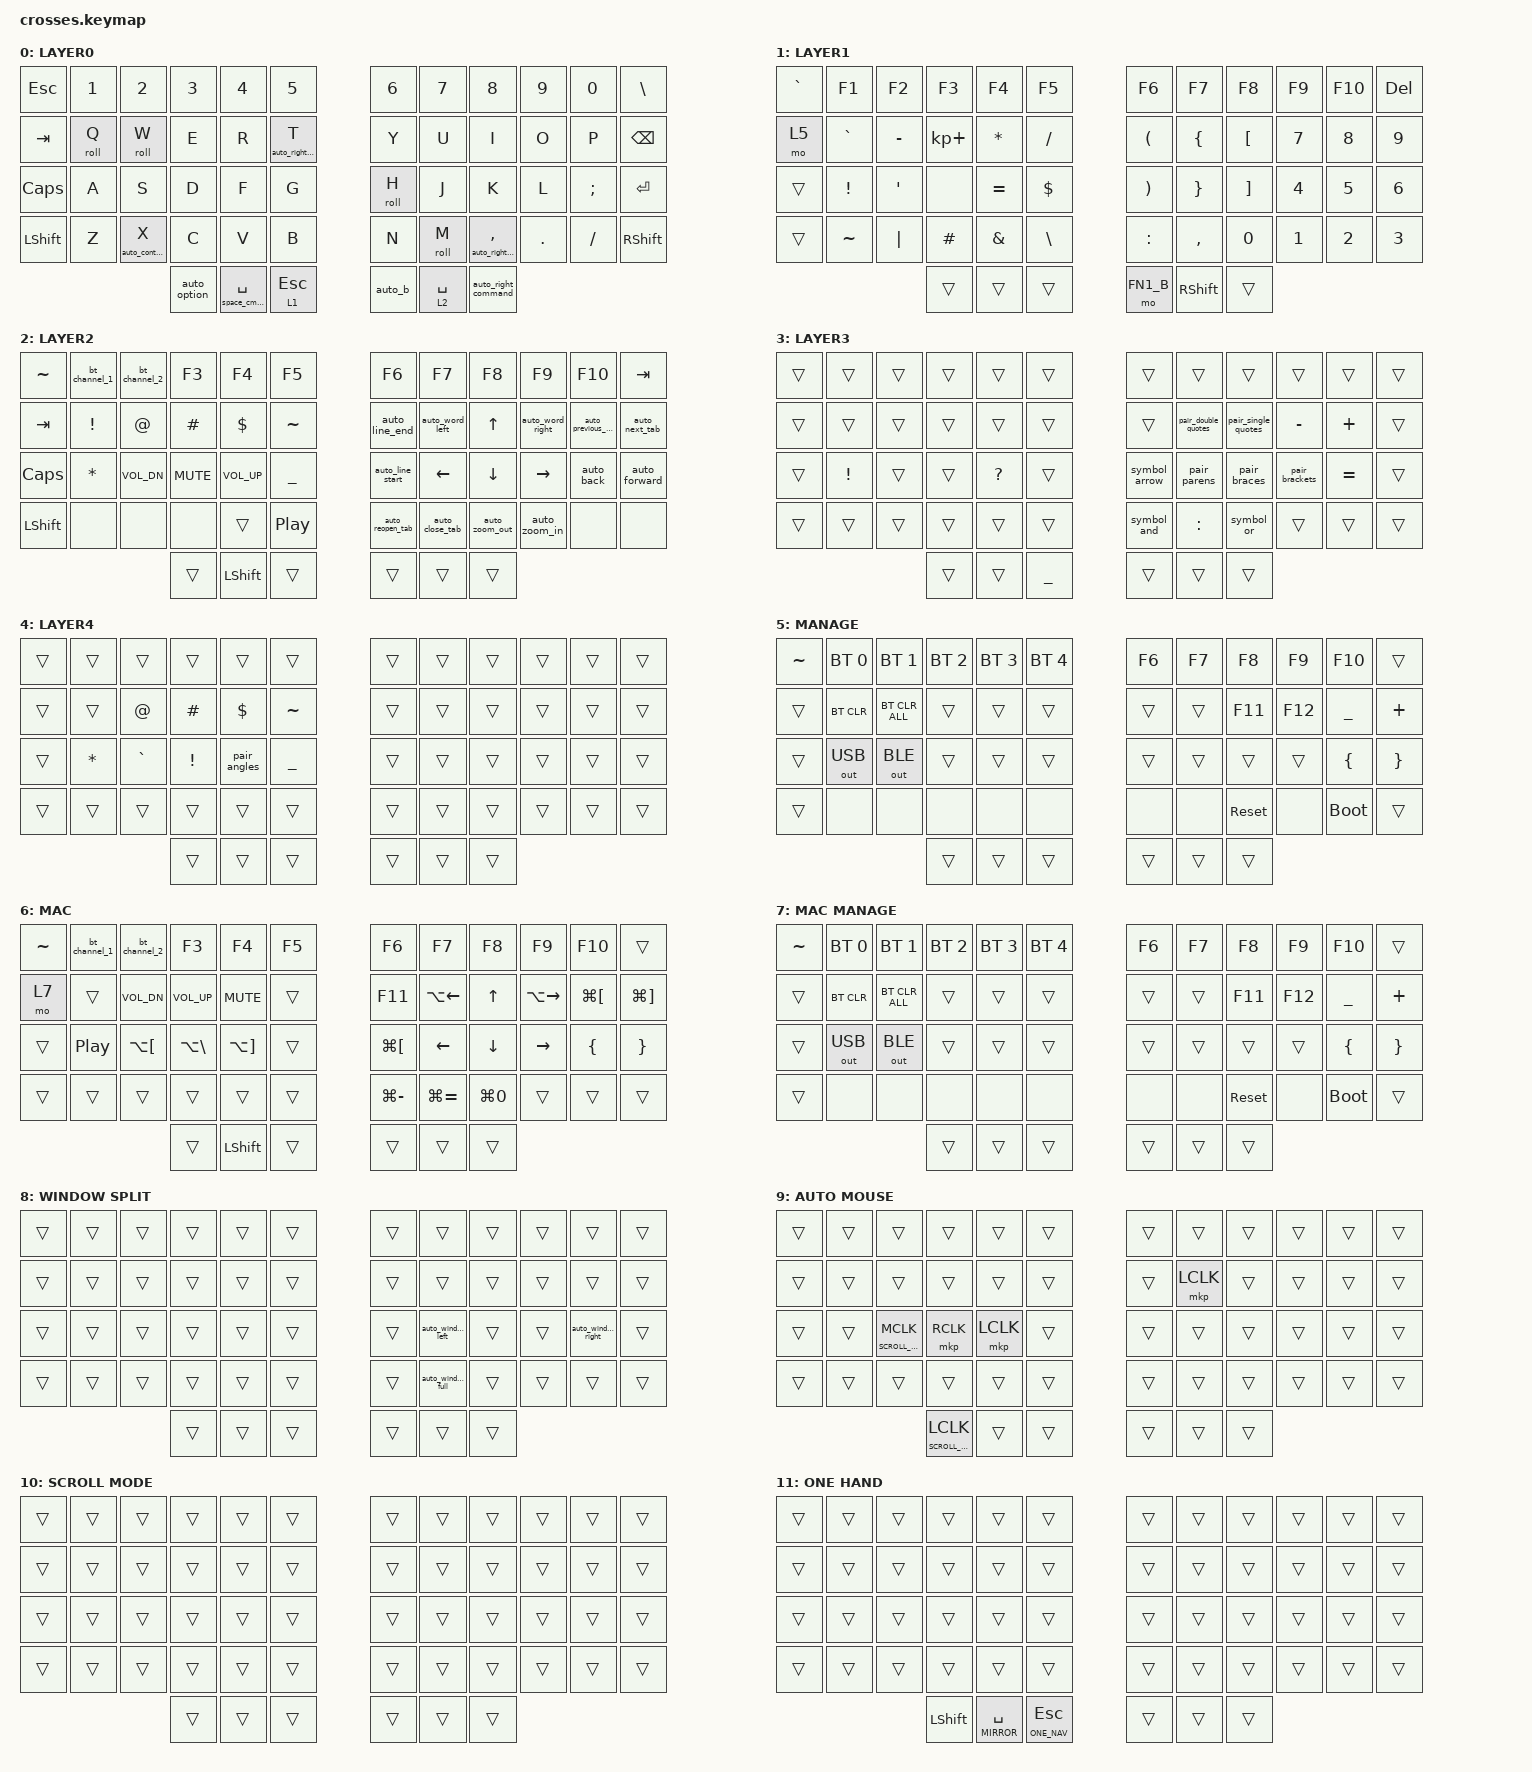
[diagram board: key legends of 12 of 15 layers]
/*
 * Crosses 54 keymap ported from semi1204/sofle-keyboard-config (codex/ctrl-rightclick-thumb, f4feaf1).
 * Sofle middle column, encoders, RGB and soft-off do not exist on Crosses.
 * Thumbs: L Option / Space-Cmd / Fn1-Esc, R B-Ctrl / Space-Fn2 / RCmd.
 */

#include <behaviors.dtsi>
#include <input/processors.dtsi>
#include <dt-bindings/zmk/bt.h>
#include <dt-bindings/zmk/keys.h>
#include <dt-bindings/zmk/outputs.h>
#include <dt-bindings/zmk/pointing.h>
#include <dt-bindings/zmk/input_transform.h>
#include <zephyr/dt-bindings/input/input-event-codes.h>

#define AUTO_MOUSE 9
#define SCROLL_MODE 10
#define ONE_HAND 11
#define MIRROR 12
#define ONE_NAV 13
#define FN1_B 14

&lt {
    flavor = "hold-preferred";
    tapping-term-ms = <150>;
};

// Moving the right (pointer) trackball turns on AUTO_MOUSE for 1000 ms after the last movement.
// Any key other than excluded-positions turns it off immediately.
&zip_temp_layer {
    require-prior-idle-ms = <300>;
    excluded-positions = <19 26 27 28 36 38 48 49>;
};

// Right ball = pointer: x1.75 (stock cpi 700 felt slow).
&trackball_central_listener {
    input-processors = <&zip_xy_scaler 7 4>, <&zip_temp_layer AUTO_MOUSE 1000>, <&zip_ble_report_rate_limit>;

    // Holding S or the left Option thumb on AUTO_MOUSE turns the right ball into a scroll wheel.
    scroll_mode {
        layers = <SCROLL_MODE>;
        input-processors = <&zip_xy_to_scroll_mapper>, <&zip_scroll_transform INPUT_TRANSFORM_Y_INVERT>, <&zip_scroll_scaler 1 32>, <&zip_temp_layer AUTO_MOUSE 1000>, <&zip_ble_report_rate_limit>;
    };

    // Fn1 + B held: one flick up on the right ball runs Screen OCR. Listed before fn1_keys because
    // the first override whose layer is active wins.
    fn1_b_keys {
        layers = <FN1_B>;
        input-processors = <&zip_xy_to_scroll_mapper>, <&zip_scroll_transform INPUT_TRANSFORM_Y_INVERT>, <&zip_scroll_scaler 1 4>, <&zip_scroll_ocr>;
    };

    // Fn1 held: the right ball is a two-way switch, one tap per flick (up = Ctrl+1, down = Option+/).
    fn1_keys {
        layers = <1>;
        input-processors = <&zip_xy_to_scroll_mapper>, <&zip_scroll_transform INPUT_TRANSFORM_Y_INVERT>, <&zip_scroll_scaler 1 4>, <&zip_scroll_fn1>;
    };
};

// Left ball = scroll at 1/32 (stock 1/4 felt too fast).
&trackball_peripheral_listener {
    input-processors = <&zip_xy_to_scroll_mapper>, <&zip_scroll_scaler 1 32>, <&zip_ble_report_rate_limit>;

    // On Fn2 the left ball zooms (Cmd +/-) instead of scrolling.
    zoom {
        layers = <2>;
        input-processors = <&zip_xy_to_scroll_mapper>, <&zip_scroll_scaler 1 4>, <&zip_scroll_zoom>;
    };
};

/ {
    chosen { zmk,physical-layout = &gggw_crosses_54_layout; };

    zip_scroll_zoom: zip_scroll_zoom {
        compatible = "zmk,input-processor-scroll-keys";
        #input-processor-cells = <0>;
        code = <INPUT_REL_WHEEL>;
        threshold = <40>;
        bindings = <&auto_zoom_in>, <&auto_zoom_out>;
    };

    // Fn1 right ball: Ctrl+1 (up) / Option+/ (down) for Screenshot X and BTT, once per flick.
    zip_scroll_fn1: zip_scroll_fn1 {
        compatible = "zmk,input-processor-scroll-keys";
        #input-processor-cells = <0>;
        code = <INPUT_REL_WHEEL>;
        threshold = <60>;
        one-shot-idle-ms = <300>;
        bindings = <&kp LC(N1)>, <&auto_option_slash>;
    };

    // Fn1 + B right ball: flick up = Option+Shift+2 (Raycast ScreenOCR hotkey).
    zip_scroll_ocr: zip_scroll_ocr {
        compatible = "zmk,input-processor-scroll-keys";
        #input-processor-cells = <0>;
        code = <INPUT_REL_WHEEL>;
        threshold = <60>;
        one-shot-idle-ms = <300>;
        bindings = <&auto_screen_ocr>, <&none>;
    };

    behaviors {
        // The Windows profile (BLE profile 1, the second slot, used by both the Windows and the Linux host)
        // sends what the laptop's own keys send at the Mac positions: Option = LGUI, Command = LALT,
        // Control = LCTRL, right Command = RALT. Each host remaps from there (Windows: SharpKeys LWin->Alt,
        // LAlt->Ctrl, LCtrl->Win plus AHK Alt+arrow word moves; Linux: kanata -> Toshy), so Option, Command
        // and Control stay distinct. Mac shortcuts with modifiers must go through a profile modifier, never a
        // raw LA()/LG().
        auto_option: auto_option {
            compatible = "zmk,behavior-profile-modifier";
            #binding-cells = <0>;
            windows-profile = <1>;
            bindings = <&kp LEFT_ALT>, <&kp LEFT_GUI>;
            display-name = "Auto Option / Win";
        };

        auto_command: auto_command {
            compatible = "zmk,behavior-profile-modifier";
            #binding-cells = <0>;
            windows-profile = <1>;
            bindings = <&kp LEFT_GUI>, <&kp LEFT_ALT>;
            display-name = "Auto Command / Alt";
        };

        // Windows host remaps raw RAlt/SC138 to Ctrl and LGUI to ordinary LAlt.
        auto_space: auto_space {
            compatible = "zmk,behavior-profile-modifier";
            #binding-cells = <0>;
            windows-profile = <1>;
            bindings = <&mt RIGHT_GUI SPACE>, <&mt RIGHT_ALT SPACE>;
            display-name = "Auto Space / Cmd-Ctrl";
        };

        space_shift: space_shift {
            compatible = "zmk,behavior-hold-tap";
            #binding-cells = <2>;
            flavor = "tap-preferred";
            tapping-term-ms = <200>;
            bindings = <&kp>, <&kp>;
            display-name = "Space / Shift";
        };

        // retro-tap: held past 150 ms and released alone still gives Space (RCmd+Space).
        space_fn2: space_fn2 {
            compatible = "zmk,behavior-hold-tap";
            #binding-cells = <2>;
            flavor = "tap-preferred";
            tapping-term-ms = <150>;
            retro-tap;
            bindings = <&mo>, <&kp>;
            display-name = "Space / Fn2";
        };

        auto_right_command: auto_right_command {
            compatible = "zmk,behavior-profile-modifier";
            #binding-cells = <0>;
            windows-profile = <1>;
            bindings = <&kp RIGHT_GUI>, <&kp RIGHT_ALT>;
            display-name = "Auto Right Command / Ctrl";
        };

        auto_right_alt: auto_right_alt {
            compatible = "zmk,behavior-profile-modifier";
            #binding-cells = <0>;
            windows-profile = <1>;
            bindings = <&kp RIGHT_ALT>, <&kp LEFT_GUI>;
            display-name = "Auto Right Alt / Alt";
        };

        // Control is LCTRL on both profiles.
        auto_control: auto_control {
            compatible = "zmk,behavior-profile-modifier";
            #binding-cells = <0>;
            windows-profile = <1>;
            bindings = <&kp LCTRL>, <&kp LCTRL>;
            display-name = "Auto Control";
        };

        // B follows typing like Space: within 250 ms of a key it is always B; after a pause, any key
        // pressed while it is held is Ctrl+key at once; a long press released alone still gives B.
        b_ctrl: b_ctrl {
            compatible = "zmk,behavior-hold-tap";
            #binding-cells = <2>;
            flavor = "hold-preferred";
            tapping-term-ms = <200>;
            quick-tap-ms = <175>;
            require-prior-idle-ms = <250>;
            retro-tap;
            bindings = <&kp>, <&kp>;
            display-name = "Hold Control / Tap B";
        };

        // B/Control is LCTRL on both profiles.
        auto_b: auto_b {
            compatible = "zmk,behavior-profile-modifier";
            #binding-cells = <0>;
            windows-profile = <1>;
            bindings = <&b_ctrl LCTRL B>, <&b_ctrl LCTRL B>;
            display-name = "Auto B / Ctrl";
        };

        auto_back: auto_back {
            compatible = "zmk,behavior-profile-modifier";
            #binding-cells = <0>;
            windows-profile = <1>;
            bindings = <&kp LG(LEFT_BRACKET)>, <&kp C_AC_BACK>;
            display-name = "Auto Back";
        };

        auto_forward: auto_forward {
            compatible = "zmk,behavior-profile-modifier";
            #binding-cells = <0>;
            windows-profile = <1>;
            bindings = <&kp LG(RIGHT_BRACKET)>, <&kp C_AC_FORWARD>;
            display-name = "Auto Forward";
        };

        // This Windows host maps raw Left Alt to Ctrl.
        auto_previous_tab: auto_previous_tab {
            compatible = "zmk,behavior-profile-modifier";
            #binding-cells = <0>;
            windows-profile = <1>;
            bindings = <&kp LG(LS(LEFT_BRACKET))>, <&kp LA(PG_UP)>;
            display-name = "Auto Previous Tab";
        };

        auto_next_tab: auto_next_tab {
            compatible = "zmk,behavior-profile-modifier";
            #binding-cells = <0>;
            windows-profile = <1>;
            bindings = <&kp LG(LS(RIGHT_BRACKET))>, <&kp LA(PG_DN)>;
            display-name = "Auto Next Tab";
        };

        auto_reopen_tab: auto_reopen_tab {
            compatible = "zmk,behavior-profile-modifier";
            #binding-cells = <0>;
            windows-profile = <1>;
            bindings = <&kp LG(LS(T))>, <&kp LA(LS(T))>;
            display-name = "Auto Reopen Tab";
        };

        auto_close_tab: auto_close_tab {
            compatible = "zmk,behavior-profile-modifier";
            #binding-cells = <0>;
            windows-profile = <1>;
            bindings = <&kp LG(W)>, <&kp LA(W)>;
            display-name = "Auto Close Tab";
        };

        auto_zoom_in: auto_zoom_in {
            compatible = "zmk,behavior-profile-modifier";
            #binding-cells = <0>;
            windows-profile = <1>;
            bindings = <&kp LG(EQUAL)>, <&kp LA(EQUAL)>;
            display-name = "Auto Zoom In";
        };

        auto_zoom_out: auto_zoom_out {
            compatible = "zmk,behavior-profile-modifier";
            #binding-cells = <0>;
            windows-profile = <1>;
            bindings = <&kp LG(MINUS)>, <&kp LA(MINUS)>;
            display-name = "Auto Zoom Out";
        };

        auto_undo: auto_undo {
            compatible = "zmk,behavior-profile-modifier";
            #binding-cells = <0>;
            windows-profile = <1>;
            bindings = <&kp LG(Z)>, <&kp LA(Z)>;
            display-name = "Auto Undo";
        };

        auto_cut: auto_cut {
            compatible = "zmk,behavior-profile-modifier";
            #binding-cells = <0>;
            windows-profile = <1>;
            bindings = <&kp LG(X)>, <&kp LA(X)>;
            display-name = "Auto Cut";
        };

        auto_copy: auto_copy {
            compatible = "zmk,behavior-profile-modifier";
            #binding-cells = <0>;
            windows-profile = <1>;
            bindings = <&kp LG(C)>, <&kp LA(C)>;
            display-name = "Auto Copy";
        };

        auto_paste: auto_paste {
            compatible = "zmk,behavior-profile-modifier";
            #binding-cells = <0>;
            windows-profile = <1>;
            bindings = <&kp LG(V)>, <&kp LA(V)>;
            display-name = "Auto Paste";
        };

        // One-shot modifiers for ONE_NAV, same host mapping as auto_command/auto_option/auto_control.
        sticky_command: sticky_command {
            compatible = "zmk,behavior-profile-modifier";
            #binding-cells = <0>;
            windows-profile = <1>;
            bindings = <&sk LEFT_GUI>, <&sk LEFT_ALT>;
            display-name = "Sticky Command";
        };

        sticky_option: sticky_option {
            compatible = "zmk,behavior-profile-modifier";
            #binding-cells = <0>;
            windows-profile = <1>;
            bindings = <&sk LEFT_ALT>, <&sk LEFT_GUI>;
            display-name = "Sticky Option";
        };

        // Control is LCTRL on both profiles.
        sticky_control: sticky_control {
            compatible = "zmk,behavior-profile-modifier";
            #binding-cells = <0>;
            windows-profile = <1>;
            bindings = <&sk LCTRL>, <&sk LCTRL>;
            display-name = "Sticky Control";
        };

        auto_line_start: auto_line_start {
            compatible = "zmk,behavior-profile-modifier";
            #binding-cells = <0>;
            windows-profile = <1>;
            bindings = <&kp LG(LEFT)>, <&kp HOME>;
            display-name = "Auto Line Start";
        };

        auto_line_end: auto_line_end {
            compatible = "zmk,behavior-profile-modifier";
            #binding-cells = <0>;
            windows-profile = <1>;
            bindings = <&kp LG(RIGHT)>, <&kp END>;
            display-name = "Auto Line End";
        };

        // Option+arrow word moves (Windows: SharpKeys turns LGUI into Alt, then AHK turns Alt+arrow into Ctrl+arrow;
        // Toshy does the same on Linux).
        auto_word_left: auto_word_left {
            compatible = "zmk,behavior-profile-modifier";
            #binding-cells = <0>;
            windows-profile = <1>;
            bindings = <&kp LA(LEFT)>, <&kp LG(LEFT)>;
            display-name = "Auto Word Left";
        };

        auto_word_right: auto_word_right {
            compatible = "zmk,behavior-profile-modifier";
            #binding-cells = <0>;
            windows-profile = <1>;
            bindings = <&kp LA(RIGHT)>, <&kp LG(RIGHT)>;
            display-name = "Auto Word Right";
        };

        auto_select_word_right: auto_select_word_right {
            compatible = "zmk,behavior-profile-modifier";
            #binding-cells = <0>;
            windows-profile = <1>;
            bindings = <&kp LA(LS(RIGHT))>, <&kp LG(LS(RIGHT))>;
            display-name = "Auto Select Word Right";
        };

        auto_paste_style: auto_paste_style {
            compatible = "zmk,behavior-profile-modifier";
            #binding-cells = <0>;
            windows-profile = <1>;
            bindings = <&kp LG(LS(V))>, <&kp LA(LS(V))>;
            display-name = "Auto Paste and Match Style";
        };

        auto_window_left: auto_window_left {
            compatible = "zmk,behavior-profile-modifier";
            #binding-cells = <0>;
            windows-profile = <1>;
            bindings = <&kp LA(LEFT_BRACKET)>, <&kp LC(LEFT)>;
            display-name = "Auto Window Left";
        };

        auto_window_right: auto_window_right {
            compatible = "zmk,behavior-profile-modifier";
            #binding-cells = <0>;
            windows-profile = <1>;
            bindings = <&kp LA(RIGHT_BRACKET)>, <&kp LC(RIGHT)>;
            display-name = "Auto Window Right";
        };

        auto_window_full: auto_window_full {
            compatible = "zmk,behavior-profile-modifier";
            #binding-cells = <0>;
            windows-profile = <1>;
            bindings = <&kp LA(BSLH)>, <&kp LC(UP)>;
            display-name = "Auto Window Full";
        };

        auto_option_slash: auto_option_slash {
            compatible = "zmk,behavior-profile-modifier";
            #binding-cells = <0>;
            windows-profile = <1>;
            bindings = <&kp LA(FSLH)>, <&kp LG(FSLH)>;
            display-name = "Auto Option Slash";
        };

        // Raycast ScreenOCR hotkey: Option+Shift+2.
        auto_screen_ocr: auto_screen_ocr {
            compatible = "zmk,behavior-profile-modifier";
            #binding-cells = <0>;
            windows-profile = <1>;
            bindings = <&kp LA(LS(N2))>, <&kp LG(LS(N2))>;
            display-name = "Auto Screen OCR";
        };

        layer_click: layer_click {
            compatible = "zmk,behavior-hold-tap";
            #binding-cells = <2>;
            flavor = "tap-preferred";
            tapping-term-ms = <200>;
            bindings = <&mo>, <&mkp>;
            display-name = "Layer Click";
        };

        hold_ctrl: hold_ctrl {
            compatible = "zmk,behavior-hold-tap";
            #binding-cells = <2>;
            flavor = "tap-preferred";
            tapping-term-ms = <350>;
            bindings = <&auto_control>, <&kp>;
            display-name = "Hold Control / Tap Key";
        };

        hold_right_alt: hold_right_alt {
            compatible = "zmk,behavior-hold-tap";
            #binding-cells = <2>;
            flavor = "tap-preferred";
            tapping-term-ms = <350>;
            bindings = <&auto_right_alt>, <&kp>;
            display-name = "Hold Right Option / Tap Key";
        };

        // AUTO_MOUSE left thumb: tap = left click (quick re-taps for double/triple click),
        // hold past 150 ms = right-ball scroll (no Option).
        scroll_click: scroll_click {
            compatible = "zmk,behavior-hold-tap";
            #binding-cells = <2>;
            flavor = "balanced";
            tapping-term-ms = <150>;
            quick-tap-ms = <300>;
            bindings = <&mo>, <&mkp>;
            display-name = "Hold Scroll / Tap Click";
        };

        // ONE_HAND Space: any key pressed while it is down is mirrored; alone it is Space.
        space_mirror: space_mirror {
            compatible = "zmk,behavior-hold-tap";
            #binding-cells = <2>;
            flavor = "hold-preferred";
            tapping-term-ms = <200>;
            retro-tap;
            bindings = <&mo>, <&kp>;
            display-name = "Space / Mirror";
        };

        // Space follows typing: within 250 ms of a letter it is always Space. After a pause,
        // any key pressed while it is held is Cmd+key at once (release order no longer matters),
        // and a long press released alone still gives Space (so RCmd+Space works).
        // Q, W, H and M are &roll keys (modules/roll-guard): rolled into from this thumb they wait.
        // Letter released first = Cmd+letter; thumb released first = it was typing, so Space and
        // the letter are typed. That keeps typing from quitting, closing, hiding or minimizing a
        // window while a quick Cmd+W still works. After 200 ms of holding they are plain Cmd keys.
        space_cmd_hold: space_cmd_hold {
            compatible = "zmk,behavior-roll-guard-hold";
            #binding-cells = <0>;
            bindings = <&auto_command>, <&kp SPACE>;
            quick-ms = <200>;
            display-name = "Space/Command hold";
        };

        roll: roll {
            compatible = "zmk,behavior-roll-guard";
            #binding-cells = <1>;
            display-name = "Roll-safe Key";
        };

        space_cmd: space_cmd {
            compatible = "zmk,behavior-hold-tap";
            #binding-cells = <2>;
            flavor = "hold-preferred";
            tapping-term-ms = <200>;
            quick-tap-ms = <175>;
            require-prior-idle-ms = <250>;
            retro-tap;
            bindings = <&space_cmd_hold>, <&kp>;
            display-name = "Hold Command / Tap Space";
        };
    };

    combos {
        compatible = "zmk,combos";

        // Combos execute on the central (left half); MANAGE's right-hand keys reach the right half.
        combo_left_bootloader {
            timeout-ms = <50>;
            key-positions = <37 38>;
            bindings = <&bootloader>;
            layers = <5 7>;
        };
        combo_left_reset {
            timeout-ms = <50>;
            key-positions = <39 40>;
            bindings = <&sys_reset>;
            layers = <5 7>;
        };
        // Keep Fn1 Tab management access reachable even with a saved runtime keymap.
        combo_fn1_manage {
            timeout-ms = <50>;
            key-positions = <12>;
            bindings = <&mo 5>;
            layers = <1>;
        };
        // Space + Fn1/Esc thumbs toggle one-handed mode.
        combo_one_hand {
            timeout-ms = <50>;
            key-positions = <49 50>;
            bindings = <&tog ONE_HAND>;
            layers = <0 ONE_HAND>;
        };
        combo_sd_symbols {
            timeout-ms = <50>;
            key-positions = <26 27>;
            bindings = <&mo 3>;
            layers = <0>;
        };
        combo_jn_symbols {
            timeout-ms = <50>;
            key-positions = <31 42>;
            bindings = <&mo 4>;
            layers = <0>;
        };
        combo_kl_option {
            timeout-ms = <50>;
            key-positions = <32 33>;
            bindings = <&mo 8>;
            layers = <0>;
        };
        combo_df_command {
            timeout-ms = <50>;
            key-positions = <27 28>;
            bindings = <&auto_right_command>;
            layers = <0 ONE_HAND>;
        };
        combo_jk_delete_word {
            timeout-ms = <50>;
            key-positions = <31 32>;
            bindings = <&delete_word>;
            layers = <0>;
        };
        // JK mirrored for one-handed mode: hold Space, then D+F.
        combo_mirror_delete_word {
            timeout-ms = <50>;
            key-positions = <27 28>;
            bindings = <&delete_word>;
            layers = <MIRROR>;
        };
        combo_jl_delete_line {
            timeout-ms = <50>;
            key-positions = <31 33>;
            bindings = <&delete_line>;
            layers = <0>;
        };
        combo_zx_caps_lock {
            timeout-ms = <50>;
            key-positions = <37 38>;
            bindings = <&kp CAPS>;
            layers = <0>;
        };
        combo_xc_escape {
            timeout-ms = <30>;
            key-positions = <38 39>;
            bindings = <&kp ESC>;
            layers = <0>;
        };
        combo_paste_style {
            timeout-ms = <50>;
            key-positions = <34 35>;
            bindings = <&auto_paste_style>;
            layers = <0>;
        };
        combo_qw_escape {
            timeout-ms = <30>;
            key-positions = <13 14>;
            bindings = <&kp ESC>;
            layers = <0>;
        };
        combo_comma_dot_enter {
            timeout-ms = <50>;
            key-positions = <44 45>;
            bindings = <&kp ENTER>;
            layers = <0>;
        };
    };

    macros {
        bt_channel_1: bt_channel_1 {
            compatible = "zmk,behavior-macro";
            #binding-cells = <0>;
            tap-ms = <0>;
            wait-ms = <0>;
            bindings = <&bt BT_SEL 0 &out OUT_BLE>;
            display-name = "Bluetooth 1 (Mac)";
        };
        bt_channel_2: bt_channel_2 {
            compatible = "zmk,behavior-macro";
            #binding-cells = <0>;
            tap-ms = <0>;
            wait-ms = <0>;
            bindings = <&bt BT_SEL 1 &out OUT_BLE>;
            display-name = "Bluetooth 2 (Windows)";
        };

        pair_parens: pair_parens {
            compatible = "zmk,behavior-macro";
            #binding-cells = <0>;
            tap-ms = <40>;
            wait-ms = <40>;
            bindings = <&kp LPAR &kp RPAR &kp LEFT>;
        };
        pair_braces: pair_braces {
            compatible = "zmk,behavior-macro";
            #binding-cells = <0>;
            tap-ms = <40>;
            wait-ms = <40>;
            bindings = <&kp LBRC &kp RBRC &kp LEFT>;
        };
        pair_brackets: pair_brackets {
            compatible = "zmk,behavior-macro";
            #binding-cells = <0>;
            tap-ms = <40>;
            wait-ms = <40>;
            bindings = <&kp LBKT &kp RBKT &kp LEFT>;
        };
        pair_double_quotes: pair_double_quotes {
            compatible = "zmk,behavior-macro";
            #binding-cells = <0>;
            tap-ms = <40>;
            wait-ms = <40>;
            bindings = <&kp DQT &kp DQT &kp LEFT>;
        };
        pair_single_quotes: pair_single_quotes {
            compatible = "zmk,behavior-macro";
            #binding-cells = <0>;
            tap-ms = <40>;
            wait-ms = <40>;
            bindings = <&kp APOS &kp APOS &kp LEFT>;
        };
        pair_angles: pair_angles {
            compatible = "zmk,behavior-macro";
            #binding-cells = <0>;
            tap-ms = <40>;
            wait-ms = <40>;
            bindings = <&kp LT &kp GT &kp LEFT>;
        };
        delete_word: delete_word {
            compatible = "zmk,behavior-macro";
            #binding-cells = <0>;
            tap-ms = <40>;
            wait-ms = <40>;
            bindings = <&auto_word_left &auto_select_word_right &kp BACKSPACE>;
        };
        delete_line: delete_line {
            compatible = "zmk,behavior-macro";
            #binding-cells = <0>;
            tap-ms = <40>;
            wait-ms = <40>;
            bindings = <&auto_line_start &auto_line_start &kp LS(DOWN) &kp BACKSPACE>;
        };
        symbol_arrow: symbol_arrow {
            compatible = "zmk,behavior-macro";
            #binding-cells = <0>;
            tap-ms = <40>;
            wait-ms = <40>;
            bindings = <&kp EQUAL &kp GT>;
        };
        symbol_and: symbol_and {
            compatible = "zmk,behavior-macro";
            #binding-cells = <0>;
            tap-ms = <40>;
            wait-ms = <40>;
            bindings = <&kp AMPERSAND &kp AMPERSAND>;
        };
        symbol_or: symbol_or {
            compatible = "zmk,behavior-macro";
            #binding-cells = <0>;
            tap-ms = <40>;
            wait-ms = <40>;
            bindings = <&kp PIPE &kp PIPE>;
        };

        SHIFT_MCLK: SHIFT_MCLK {
            compatible = "zmk,behavior-macro";
            #binding-cells = <0>;
            bindings =
                <&macro_press>,
                <&kp LEFT_SHIFT>,
                <&macro_press>,
                <&mkp MB3>,
                <&macro_pause_for_release>,
                <&macro_release>,
                <&kp LEFT_SHIFT &mkp MB3>;

            label = "SHIFT_MCLK";
        };
    };

    keymap {
        compatible = "zmk,keymap";

        layer0 {
            display-name = "LAYER0";
            bindings = <
&kp ESC              &kp N1               &kp N2               &kp N3               &kp N4               &kp N5                 &kp N6               &kp N7               &kp N8               &kp N9               &kp N0               &kp BSLH
&kp TAB              &roll Q              &roll W              &kp E                &kp R                &hold_right_alt 0 T   &kp Y                &kp U                &kp I                &kp O                &kp P                &kp BACKSPACE
&kp CAPS             &kp A                &kp S                &kp D                &kp F                &kp G                  &roll H              &kp J                &kp K                &kp L                &kp SEMI             &kp ENTER
&kp LSHFT            &kp Z                &hold_ctrl 0 X       &kp C                &kp V                &kp B                  &kp N                &roll M              &hold_right_alt 0 COMMA &kp DOT              &kp FSLH             &kp RIGHT_SHIFT
                                                               &auto_option         &space_cmd 0 SPACE   &lt 1 ESC             &auto_b              &space_fn2 2 SPACE   &auto_right_command
            >;
        };

        layer_1 {
            display-name = "LAYER1";
            bindings = <
&kp GRAVE        &kp F1           &kp F2           &kp F3           &kp F4           &kp F5             &kp F6           &kp F7           &kp F8           &kp F9           &kp F10          &kp DELETE
&mo 5            &kp GRAVE        &kp MINUS        &kp KP_PLUS      &kp STAR         &kp FSLH           &kp LPAR         &kp LBRC         &kp LBKT         &kp N7           &kp N8           &kp N9
&trans           &kp EXCL         &kp APOS         &none            &kp EQUAL        &kp DLLR           &kp RPAR         &kp RBRC         &kp RBKT         &kp N4           &kp N5           &kp N6
&trans           &kp TILDE        &kp PIPE         &kp HASH         &kp AMPS         &kp BSLH           &kp COLON        &kp COMMA        &kp N0           &kp N1           &kp N2           &kp N3
                                                   &trans           &trans           &trans             &mo FN1_B        &kp RIGHT_SHIFT  &trans
            >;
        };

        layer_2 {
            display-name = "LAYER2";
            bindings = <
&kp TILDE           &bt_channel_1       &bt_channel_2       &kp F3              &kp F4              &kp F5                &kp F6              &kp F7              &kp F8              &kp F9              &kp F10             &kp TAB
&kp TAB             &kp EXCL            &kp AT              &kp HASH            &kp DLLR            &kp TILDE             &auto_line_end      &auto_word_left     &kp UP              &auto_word_right    &auto_previous_tab  &auto_next_tab
&kp CAPS            &kp STAR            &kp C_VOL_DN        &kp C_MUTE          &kp C_VOL_UP        &kp UNDER             &auto_line_start    &kp LEFT            &kp DOWN            &kp RIGHT           &auto_back          &auto_forward
&kp LSHFT           &none               &none               &none               &trans              &kp C_PLAY_PAUSE      &auto_reopen_tab    &auto_close_tab     &auto_zoom_out      &auto_zoom_in       &none               &none
                                                            &trans              &kp LSHFT           &trans                &trans              &trans              &trans
            >;
        };

        layer_3 {
            display-name = "LAYER3";
            bindings = <
&trans               &trans               &trans               &trans               &trans               &trans                 &trans               &trans               &trans               &trans               &trans               &trans
&trans               &trans               &trans               &trans               &trans               &trans                 &trans               &pair_double_quotes  &pair_single_quotes  &kp MINUS            &kp PLUS             &trans
&trans               &kp EXCL             &trans               &trans               &kp QMARK            &trans                 &symbol_arrow        &pair_parens         &pair_braces         &pair_brackets       &kp EQUAL            &trans
&trans               &trans               &trans               &trans               &trans               &trans                 &symbol_and          &kp COLON            &symbol_or           &trans               &trans               &trans
                                                               &trans               &trans               &kp UNDER              &trans               &trans               &trans
            >;
        };

        layer_4 {
            display-name = "LAYER4";
            bindings = <
&trans        &trans        &trans        &trans        &trans        &trans          &trans        &trans        &trans        &trans        &trans        &trans
&trans        &trans        &kp AT        &kp HASH      &kp DLLR      &kp TILDE       &trans        &trans        &trans        &trans        &trans        &trans
&trans        &kp STAR      &kp GRAVE     &kp EXCL      &pair_angles  &kp UNDER       &trans        &trans        &trans        &trans        &trans        &trans
&trans        &trans        &trans        &trans        &trans        &trans          &trans        &trans        &trans        &trans        &trans        &trans
                                          &trans        &trans        &trans          &trans        &trans        &trans
            >;
        };

        layer_5 {
            display-name = "MANAGE";
            bindings = <
&kp TILDE       &bt BT_SEL 0    &bt BT_SEL 1    &bt BT_SEL 2    &bt BT_SEL 3    &bt BT_SEL 4      &kp F6          &kp F7          &kp F8          &kp F9          &kp F10         &trans
&trans          &bt BT_CLR      &bt BT_CLR_ALL  &trans          &trans          &trans            &trans          &trans          &kp F11         &kp F12         &kp UNDER       &kp PLUS
&trans          &out OUT_USB    &out OUT_BLE    &trans          &trans          &trans            &trans          &trans          &trans          &trans          &kp LBRC        &kp RBRC
&trans          &none           &none           &none           &none           &none             &none           &none           &sys_reset      &none           &bootloader     &trans
                                                &trans          &trans          &trans            &trans          &trans          &trans
            >;
        };

        layer_6 {
            display-name = "MAC";
            bindings = <
&kp TILDE              &bt_channel_1          &bt_channel_2          &kp F3                 &kp F4                 &kp F5                   &kp F6                 &kp F7                 &kp F8                 &kp F9                 &kp F10                &trans
&mo 7                  &trans                 &kp C_VOL_DN           &kp C_VOL_UP           &kp C_MUTE             &trans                   &kp F11                &kp LA(LEFT)           &kp UP                 &kp LA(RIGHT)          &kp LG(LEFT_BRACKET)   &kp LG(RIGHT_BRACKET)
&trans                 &kp C_PLAY_PAUSE       &kp LA(LEFT_BRACKET)   &kp LA(BSLH)           &kp LA(RIGHT_BRACKET)  &trans                   &kp LG(LEFT_BRACKET)   &kp LEFT               &kp DOWN               &kp RIGHT              &kp LBRC               &kp RBRC
&trans                 &trans                 &trans                 &trans                 &trans                 &trans                   &kp LG(MINUS)          &kp LG(EQUAL)          &kp LG(N0)             &trans                 &trans                 &trans
                                                                     &trans                 &kp LEFT_SHIFT         &trans                   &trans                 &trans                 &trans
            >;
        };

        layer_7 {
            display-name = "MAC MANAGE";
            bindings = <
&kp TILDE       &bt BT_SEL 0    &bt BT_SEL 1    &bt BT_SEL 2    &bt BT_SEL 3    &bt BT_SEL 4      &kp F6          &kp F7          &kp F8          &kp F9          &kp F10         &trans
&trans          &bt BT_CLR      &bt BT_CLR_ALL  &trans          &trans          &trans            &trans          &trans          &kp F11         &kp F12         &kp UNDER       &kp PLUS
&trans          &out OUT_USB    &out OUT_BLE    &trans          &trans          &trans            &trans          &trans          &trans          &trans          &kp LBRC        &kp RBRC
&trans          &none           &none           &none           &none           &none             &none           &none           &sys_reset      &none           &bootloader     &trans
                                                &trans          &trans          &trans            &trans          &trans          &trans
            >;
        };

        layer_8 {
            display-name = "WINDOW SPLIT";
            bindings = <
&trans              &trans              &trans              &trans              &trans              &trans                &trans              &trans              &trans              &trans              &trans              &trans
&trans              &trans              &trans              &trans              &trans              &trans                &trans              &trans              &trans              &trans              &trans              &trans
&trans              &trans              &trans              &trans              &trans              &trans                &trans              &auto_window_left   &trans              &trans              &auto_window_right  &trans
&trans              &trans              &trans              &trans              &trans              &trans                &trans              &auto_window_full   &trans              &trans              &trans              &trans
                                                            &trans              &trans              &trans                &trans              &trans              &trans
            >;
        };

        auto_mouse {
            display-name = "AUTO MOUSE";
            bindings = <
&trans     &trans     &trans     &trans     &trans     &trans       &trans     &trans     &trans     &trans     &trans     &trans
&trans     &trans     &trans     &trans     &trans     &trans       &trans     &mkp LCLK  &trans     &trans     &trans     &trans
&trans     &trans     &layer_click SCROLL_MODE MCLK  &mkp RCLK  &mkp LCLK  &trans       &trans     &trans     &trans     &trans     &trans     &trans
&trans     &trans     &trans     &trans     &trans     &trans       &trans     &trans     &trans     &trans     &trans     &trans
                                 &scroll_click SCROLL_MODE LCLK  &trans     &trans       &trans     &trans     &trans
            >;
        };

        scroll_mode {
            display-name = "SCROLL MODE";
            bindings = <
&trans     &trans     &trans     &trans     &trans     &trans       &trans     &trans     &trans     &trans     &trans     &trans
&trans     &trans     &trans     &trans     &trans     &trans       &trans     &trans     &trans     &trans     &trans     &trans
&trans     &trans     &trans     &trans     &trans     &trans       &trans     &trans     &trans     &trans     &trans     &trans
&trans     &trans     &trans     &trans     &trans     &trans       &trans     &trans     &trans     &trans     &trans     &trans
                                 &trans     &trans     &trans       &trans     &trans     &trans
            >;
        };

        // Left half alone: Space thumb taps Space / holds MIRROR, Option thumb becomes Shift,
        // Fn1/Esc thumb taps Esc / holds ONE_NAV. D+F stays right Command, the launcher modifier.
        one_hand {
            display-name = "ONE HAND";
            bindings = <
&trans     &trans     &trans     &trans     &trans     &trans       &trans     &trans     &trans     &trans     &trans     &trans
&trans     &trans     &trans     &trans     &trans     &trans       &trans     &trans     &trans     &trans     &trans     &trans
&trans     &trans     &trans     &trans     &trans     &trans       &trans     &trans     &trans     &trans     &trans     &trans
&trans     &trans     &trans     &trans     &trans     &trans       &trans     &trans     &trans     &trans     &trans     &trans
                                 &kp LSHFT  &space_mirror MIRROR SPACE  &lt ONE_NAV ESC  &trans     &trans     &trans
            >;
        };

        // Half-QWERTY: each left key types the right-hand key in the mirrored spot.
        mirror {
            display-name = "MIRROR";
            bindings = <
&kp BSLH       &kp N0         &kp N9         &kp N8         &kp N7         &kp N6           &trans     &trans     &trans     &trans     &trans     &trans
&kp BACKSPACE  &kp P          &kp O          &kp I          &kp U          &kp Y            &trans     &trans     &trans     &trans     &trans     &trans
&kp ENTER      &kp SEMI       &kp L          &kp K          &kp J          &kp H            &trans     &trans     &trans     &trans     &trans     &trans
&kp LSHFT      &kp FSLH       &kp DOT        &kp COMMA      &kp M          &kp N            &trans     &trans     &trans     &trans     &trans     &trans
                                             &trans         &trans         &trans           &trans     &trans     &trans
            >;
        };

        // ONE_HAND Fn1/Esc hold: arrows on ESDF, edit shortcuts on ZXCV, one-shot Ctrl/Option/Command on Q/T/B.
        one_nav {
            display-name = "ONE NAV";
            bindings = <
&trans           &trans           &trans           &trans           &trans           &trans             &trans     &trans     &trans     &trans     &trans     &trans
&trans           &sticky_control  &auto_word_left  &kp UP           &auto_word_right &sticky_option     &trans     &trans     &trans     &trans     &trans     &trans
&trans           &auto_line_start &kp LEFT         &kp DOWN         &kp RIGHT        &auto_line_end     &trans     &trans     &trans     &trans     &trans     &trans
&trans           &auto_undo       &auto_cut        &auto_copy       &auto_paste      &sticky_command    &trans     &trans     &trans     &trans     &trans     &trans
                                                   &trans           &trans           &trans             &trans     &trans     &trans
            >;
        };

        // Fn1 + B held: only the right-ball override above changes; keys pass through.
        fn1_b {
            display-name = "FN1 B";
            bindings = <
&trans     &trans     &trans     &trans     &trans     &trans       &trans     &trans     &trans     &trans     &trans     &trans
&trans     &trans     &trans     &trans     &trans     &trans       &trans     &trans     &trans     &trans     &trans     &trans
&trans     &trans     &trans     &trans     &trans     &trans       &trans     &trans     &trans     &trans     &trans     &trans
&trans     &trans     &trans     &trans     &trans     &trans       &trans     &trans     &trans     &trans     &trans     &trans
                                 &trans     &trans     &trans       &trans     &trans     &trans
            >;
        };
    };
};
